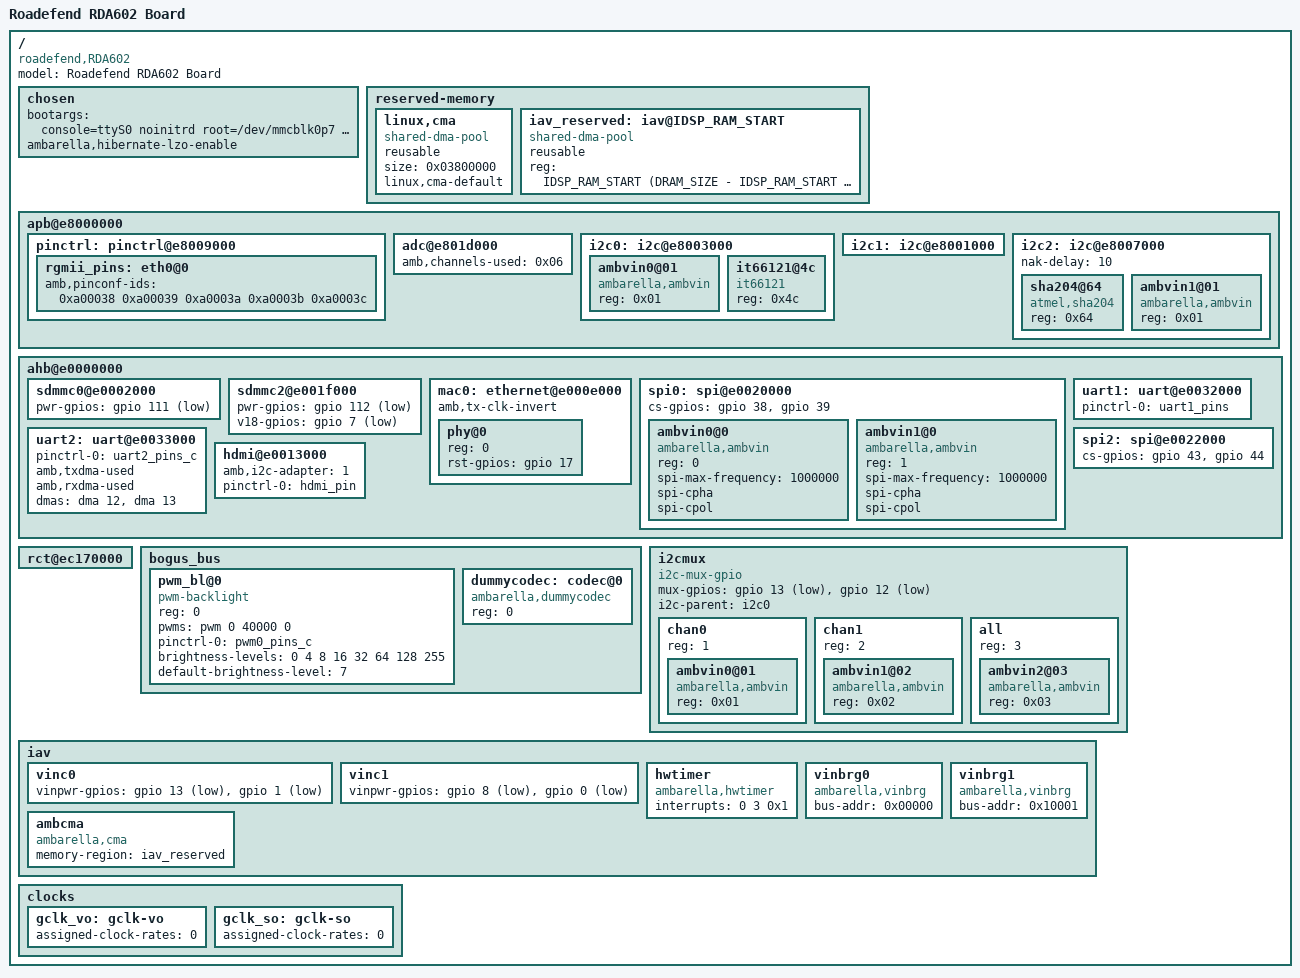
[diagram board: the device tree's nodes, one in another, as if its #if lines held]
/*
 * Copyright (C) 2013 Ambarella,Inc. - http://www.ambarella.com/
 * Author: Cao Rongrong <rrcao@ambarella.com>
 *
 * This program is free software; you can redistribute it and/or modify
 * it under the terms of the GNU General Public License version 2 as
 * published by the Free Software Foundation.
 */
/dts-v1/;

#include "config.h"
#include "bsp.h"

/include/ "ambarella-s5l.dtsi"

/ {
	model = "Roadefend RDA602 Board";
	compatible = "roadefend,RDA602", "ambarella,s5l";

	chosen {
#ifdef CONFIG_BOOT_MEDIA_EMMC
		bootargs = "console=ttyS0 noinitrd root=/dev/mmcblk0p7 rootfstype=ext4 ro";
#else
		bootargs = "console=ttyS0 ubi.mtd=lnx root=ubi0:rootfs rw rootfstype=ubifs init=/linuxrc";
#endif
		ambarella,hibernate-lzo-enable;
	};

#ifndef CONFIG_ARMV8_AARCH32
	reserved-memory {
		#address-cells = <1>;
		#size-cells = <1>;
		ranges;

		/* global autoconfigured region for contiguous allocations */
		/* size can be larged for big vout OSD framebuffer */
		linux,cma {
			compatible = "shared-dma-pool";
			reusable;
#ifdef CONFIG_AMBARELLA_IAV_DSP_MEM_RESERVED
			/* need larger size as more IAV/DSP buffers like ucode, img are put to it */
			size = <0x03800000>;
#else
			size = <0x02000000>;
#endif
			linux,cma-default;
		};

#ifndef CONFIG_AMBARELLA_IAV_DSP_MEM_RESERVED
		iav_reserved: iav@IDSP_RAM_START {
			compatible = "shared-dma-pool";
			reusable;
			reg = <IDSP_RAM_START (DRAM_SIZE - IDSP_RAM_START - 0x400000)>;
		};
#endif
	};
#endif

	apb@e8000000 {
		pinctrl: pinctrl@e8009000 {
			rgmii_pins: eth0@0 {
				amb,pinconf-ids = <0xa00038 0xa00039 0xa0003a
						  0xa0003b 0xa0003c>;
			};
		};

		adc@e801d000 {
			amb,channels-used = <0x06>; /* ch1 and ch3 */
		};

		i2c0: i2c@e8003000 {
			status = "ok";

#ifdef CONFIG_BOARD_TYPE_SINGLE_SEN
			ambvin0@01 {
				compatible = "ambarella,ambvin";
				reg = <0x01>;	/* fake address, will be overwritten in runtime */
			};
#endif
			it66121@4c {
				compatible = "it66121";
				reg = <0x4c>;
			};
		};

		i2c1: i2c@e8001000 {
			status = "ok";
	        };

		i2c2: i2c@e8007000 {
			status = "ok";

			nak-delay=<10>;
			sha204@64 {
				compatible = "atmel,sha204";
				reg = <0x64>;
			};

#ifdef CONFIG_BOARD_TYPE_SINGLE_SEN
			ambvin1@01 {
				compatible = "ambarella,ambvin";
				reg = <0x01>;
			};
#endif
		};
	};

	ahb@e0000000 {
		sdmmc0@e0002000 {
			pwr-gpios = <&gpio 111 0x1>;
		};

		sdmmc2@e001f000 {
			pwr-gpios = <&gpio 112 0x1>;
			v18-gpios = <&gpio 7 0x1>;
		};

		mac0: ethernet@e000e000 {
			amb,tx-clk-invert;
			phy@0 {
				reg = <0>;
				rst-gpios = <&gpio 17 0x0>;
			};
		};

		spi0: spi@e0020000 {
			status = "ok";
			cs-gpios = <&gpio 38 0>, <&gpio 39 0>;

			ambvin0@0 {
				compatible = "ambarella,ambvin";
				reg = <0>;
				spi-max-frequency = <1000000>;
				spi-cpha;
				spi-cpol;
			};

			ambvin1@0 {
				compatible = "ambarella,ambvin";
				reg = <1>;
				spi-max-frequency = <1000000>;
				spi-cpha;
				spi-cpol;
			};
		};

		uart1: uart@e0032000 {
			pinctrl-0 = <&uart1_pins>;
		};

		uart2: uart@e0033000 {
			pinctrl-0 = <&uart2_pins_c>;
			status = "ok";
			amb,txdma-used;
			amb,rxdma-used;
			dmas = <&dma 12>, <&dma 13>;
			dma-names = "tx", "rx";
		};

		spi2: spi@e0022000 {
			status = "ok";
			cs-gpios = <&gpio 43 0>, <&gpio 44 0>;
/*
			gyro@0 {
				compatible = "ambarella,gyro";
				reg = <1>;
				spi-max-frequency = <10000000>;
				spi-cpha;
				spi-cpol;
				irq-gpio = <&gpio 8 0>;
			};
			*/
		};

		hdmi@e0013000 {
			amb,i2c-adapter = <1>;
			pinctrl-names = "default";
			pinctrl-0 = <&hdmi_pin>;
		};
	};

	rct@ec170000 {
#if 0
		usbphy: usbphy@ec170050 {
			/* high will trigger the ocp interrupt */
			amb,ocp-polarity = <0>;
			pinctrl-names = "default";
			pinctrl-0 = <&usb_host0_pins>;
			md-gpios = <&gpio 15 0x0>;
			hub-gpios = <&gpio 16 0x0>;
		};
#endif
	};

	bogus_bus {
		pwm_bl@0 {
			compatible = "pwm-backlight";
			reg = <0>;
			pwms = <&pwm 0 40000 0>;
			pinctrl-names = "default";
			pinctrl-0 = <&pwm0_pins_c>;
			brightness-levels = <0 4 8 16 32 64 128 255>;
			default-brightness-level = <7>;
		};

		dummycodec: codec@0 {
			compatible = "ambarella,dummycodec";
			reg = <0>;
			#sound-dai-cells = <0>;
		};
	};

#ifdef CONFIG_BOARD_TYPE_DUAL_SEN
	i2cmux {
		compatible = "i2c-mux-gpio";
		#address-cells = <1>;
		#size-cells = <0>;
		mux-gpios = <&gpio 13 1>,  <&gpio 12 1>;
		i2c-parent = <&i2c0>;
		status = "ok";

		chan0 {
			reg = <1>;
			#address-cells = <1>;
			#size-cells = <0>;

			ambvin0@01 {
				compatible = "ambarella,ambvin";
				reg = <0x01>;
			};
		};

		chan1 {
			reg = <2>;
			#address-cells = <1>;
			#size-cells = <0>;

			ambvin1@02 {
				compatible = "ambarella,ambvin";
				reg = <0x02>;
			};
		};

		all {
			reg = <3>;
			#address-cells = <1>;
			#size-cells = <0>;

			ambvin2@03 {
				compatible = "ambarella,ambvin";
				reg = <0x03>;
			};
		};
	};
#endif

	iav {
		/* node for vin controller */
		vinc0 {
			/*vinrst-gpios = <&gpio 117 0>;*/
			vinpwr-gpios = <&gpio 13 1>, <&gpio 1 1>;
		};
		vinc1 {
			/*vinrst-gpios = <&gpio 14 0>;*/
			vinpwr-gpios = <&gpio 8 1>, <&gpio 0 1>;
		};
		/* node for hwtimer controller */
		hwtimer {
			compatible = "ambarella,hwtimer";
			interrupts = <0 3 0x1>;
			interrupt-names = "hwtimer";
		};
		/* node for vin bridge */
		vinbrg0 {
			compatible = "ambarella,vinbrg";
		//	brgrst-gpios = <&gpio 14 0>;
			bus-addr = <0x00000>;
		//	brgpwr-gpios = <&gpio 0 1>,<&gpio 8 1>;
		};

		vinbrg1 {
			compatible = "ambarella,vinbrg";
		//	brgrst-gpios = <&gpio 11 0>;
			bus-addr = <0x10001>;
		};

		ambcma {
			compatible = "ambarella,cma";
#ifndef CONFIG_AMBARELLA_IAV_DSP_MEM_RESERVED
			memory-region = <&iav_reserved>;
#endif
		};
	};

/*
	sound {
		compatible = "ambarella,audio-board";
		simple-audio-card,name = "ak4951 @ AMBEVK";
		simple-audio-card,mclk-fs = <256>;
		simple-audio-card,widgets =
			"Speaker", "Speaker",
			"Headphone", "HP Jack",
			"Line", "Line In",
			"Line", "Line Out",
			"Microphone", "Mic Internal",
			"Microphone", "Mic External";
		simple-audio-card,routing =
			"LIN2", "Mic Bias",
			"RIN2", "Mic Bias",
			"Mic Bias", "Mic Internal",
			"LIN3", "Line In",
			"RIN3", "Line In",
			"Line Out", "SPKLO",
			"HP Jack", "HPL",
			"HP Jack", "HPR",
			"Speaker", "SPKLO";

		simple-audio-card,dai-link@0 {
			format = "i2s";

			cpu {
				sound-dai = <&i2s0>;
			};

			codec {
				sound-dai = <&ak4951>;
			};
		};

		simple-audio-card,dai-link@1 {
			format = "i2s";

			cpu {
				sound-dai = <&i2s0>;
			};

			codec {
				sound-dai = <&dummycodec>;
			};
		};
	};
 */

	clocks {
		gclk_vo: gclk-vo { /* for tv */
			assigned-clock-rates = <0> ;
		};
#ifdef AMBOOT_DEV_FAST_BOOT
		gclk_so: gclk-so {
			assigned-clock-rates = <0> ;
		};
#endif
	};
};

